VERSION "created by canmatrix"

NS_ :

BS_:

BU_: Host RT SYS MTR PWT DCDC EPS_C SEB HMI Any

BO_ 1 SAFETY_ESTOP_high: 0 Any

BO_ 1 SAFETY_ESTOP_low: 0 Any

BO_ 273 HMI_MODE_REQ_high: 2 Host
 SG_ req_mode : 7|8@0+ (1,0) [0|1] "" RT
 SG_ rolling_counter : 15|8@0+ (1,0) [0|255] "" RT

BO_ 274 HMI_PWR_REQ_high: 2 Host
 SG_ req_start : 7|8@0+ (1,0) [0|1] "" RT
 SG_ rolling_counter : 15|8@0+ (1,0) [0|255] "" RT

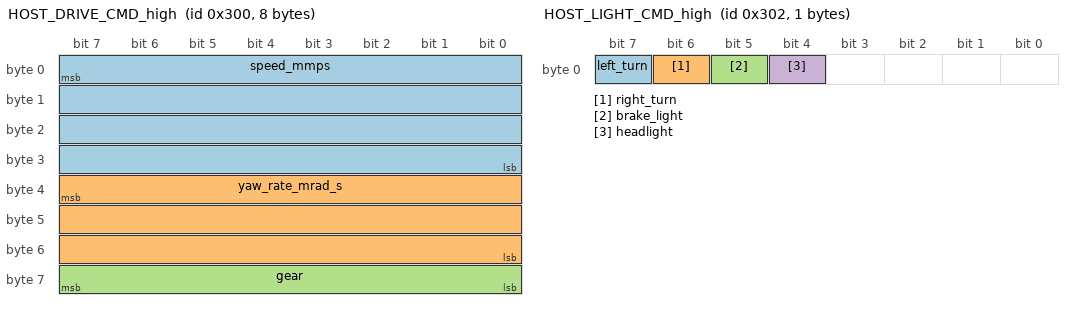
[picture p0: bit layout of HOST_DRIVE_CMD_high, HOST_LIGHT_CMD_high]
BO_ 768 HOST_DRIVE_CMD_high: 8 Host
 SG_ speed_mmps : 7|32@0- (1,0) [-500|3000] "" RT
 SG_ yaw_rate_mrad_s : 39|24@0- (1,0) [-3000|3000] "" RT
 SG_ gear : 63|8@0+ (1,0) [0|3] "" RT

BO_ 769 HOST_BRAKE_REQ_high: 4 Host
 SG_ brake_pressure_kpa : 7|32@0- (1,0) [0|20000] "" RT

BO_ 770 HOST_LIGHT_CMD_high: 1 Host
 SG_ left_turn : 7|1@0+ (1,0) [0|1] "" RT,SYS
 SG_ right_turn : 6|1@0+ (1,0) [0|1] "" RT,SYS
 SG_ brake_light : 5|1@0+ (1,0) [0|1] "" RT,SYS
 SG_ headlight : 4|1@0+ (1,0) [0|1] "" RT,SYS

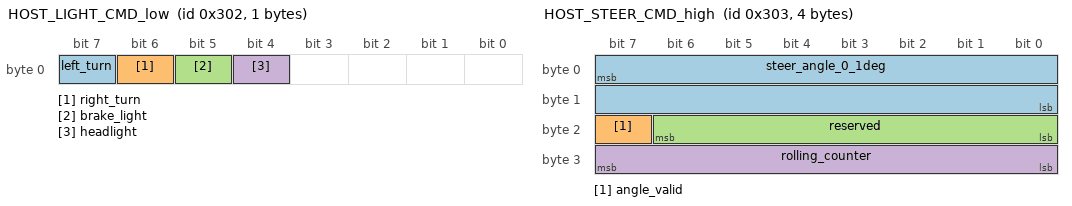
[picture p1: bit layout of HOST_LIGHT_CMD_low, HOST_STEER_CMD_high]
BO_ 770 HOST_LIGHT_CMD_low: 1 Host
 SG_ left_turn : 7|1@0+ (1,0) [0|1] "" RT,SYS
 SG_ right_turn : 6|1@0+ (1,0) [0|1] "" RT,SYS
 SG_ brake_light : 5|1@0+ (1,0) [0|1] "" RT,SYS
 SG_ headlight : 4|1@0+ (1,0) [0|1] "" RT,SYS

BO_ 771 HOST_STEER_CMD_high: 4 Host
 SG_ steer_angle_0_1deg : 7|16@0- (1,0) [-450|450] "" RT
 SG_ angle_valid : 23|1@0+ (1,0) [0|1] "" RT
 SG_ reserved : 22|7@0+ (1,0) [0|127] "" RT
 SG_ rolling_counter : 31|8@0+ (1,0) [0|255] "" RT

BO_ 1024 HOST_OBSTACLE_DIST_high: 4 Host
 SG_ distance_mm : 7|32@0+ (1,0) [0|4294967295] "" RT

BO_ 2044 HOST_HEARTBEAT_high: 2 Host
 SG_ alive_ctr : 7|8@0+ (1,0) [0|255] "" RT
 SG_ health_flags : 15|8@0+ (1,0) [0|255] "" RT

BO_ 288 SYS_THROTTLE_STS_low: 2 MTR
 SG_ speed_mmps : 7|16@0- (1,0) [-500|3000] "" RT,Host

BO_ 288 SYS_THROTTLE_STS_high: 2 MTR
 SG_ speed_mmps : 7|16@0- (1,0) [-500|3000] "" RT,Host

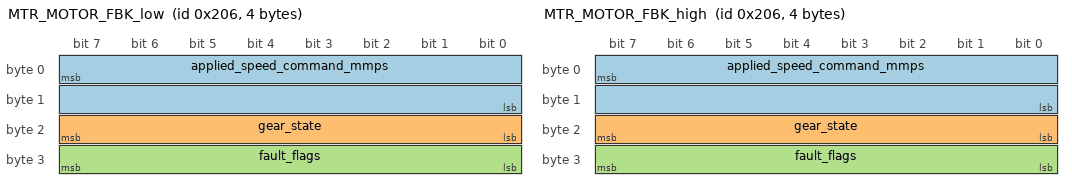
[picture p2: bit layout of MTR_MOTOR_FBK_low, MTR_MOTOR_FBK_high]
BO_ 518 MTR_MOTOR_FBK_low: 4 MTR
 SG_ applied_speed_command_mmps : 7|16@0- (1,0) [-500|3000] "" RT,SYS,Host
 SG_ gear_state : 23|8@0+ (1,0) [0|3] "" RT,SYS,Host
 SG_ fault_flags : 31|8@0+ (1,0) [0|255] "" RT,SYS,Host

BO_ 518 MTR_MOTOR_FBK_high: 4 MTR
 SG_ applied_speed_command_mmps : 7|16@0- (1,0) [-500|3000] "" RT,SYS,Host
 SG_ gear_state : 23|8@0+ (1,0) [0|3] "" RT,SYS,Host
 SG_ fault_flags : 31|8@0+ (1,0) [0|255] "" RT,SYS,Host

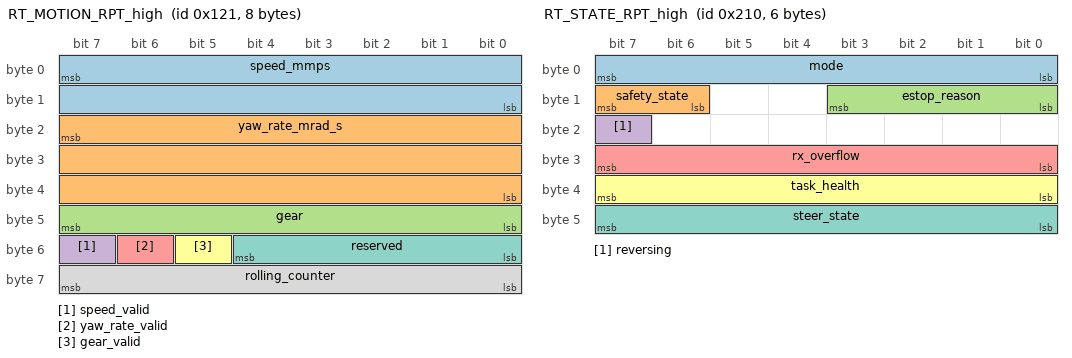
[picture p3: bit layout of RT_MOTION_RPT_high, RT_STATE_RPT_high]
BO_ 289 RT_MOTION_RPT_high: 8 RT
 SG_ speed_mmps : 7|16@0- (1,0) [-500|3000] "" Host
 SG_ yaw_rate_mrad_s : 23|24@0- (1,0) [-3000|3000] "" Host
 SG_ gear : 47|8@0+ (1,0) [0|3] "" Host
 SG_ speed_valid : 55|1@0+ (1,0) [0|1] "" Host
 SG_ yaw_rate_valid : 54|1@0+ (1,0) [0|1] "" Host
 SG_ gear_valid : 53|1@0+ (1,0) [0|1] "" Host
 SG_ reserved : 52|5@0+ (1,0) [0|31] "" Host
 SG_ rolling_counter : 63|8@0+ (1,0) [0|255] "" Host

BO_ 516 RT_DRIVE_CMD_low: 5 RT
 SG_ motor_speed_mmps : 7|32@0- (1,0) [-500|3000] "" SYS,MTR
 SG_ gear : 39|8@0+ (1,0) [0|3] "" SYS,MTR

BO_ 517 RT_BRAKE_CMD_low: 4 RT
 SG_ brake_pressure_kpa : 7|32@0- (1,0) [0|20000] "" SYS

BO_ 528 RT_STATE_RPT_high: 6 RT
 SG_ mode : 7|8@0+ (1,0) [0|2] "" Host,SYS
 SG_ safety_state : 15|2@0+ (1,0) [0|2] "" Host,SYS
 SG_ estop_reason : 11|4@0+ (1,0) [0|7] "" Host,SYS
 SG_ reversing : 23|1@0+ (1,0) [0|1] "" Host,SYS
 SG_ rx_overflow : 31|8@0+ (1,0) [0|255] "" Host,SYS
 SG_ task_health : 39|8@0+ (1,0) [0|255] "" Host,SYS
 SG_ steer_state : 47|8@0+ (1,0) [0|5] "" Host,SYS

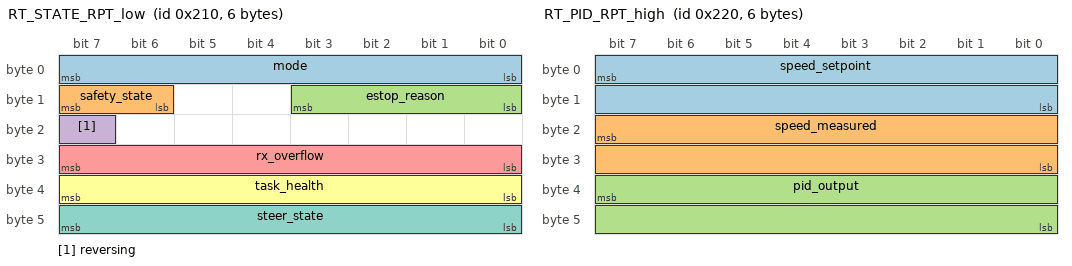
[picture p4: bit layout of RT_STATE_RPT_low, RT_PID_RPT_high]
BO_ 528 RT_STATE_RPT_low: 6 RT
 SG_ mode : 7|8@0+ (1,0) [0|2] "" Host,SYS
 SG_ safety_state : 15|2@0+ (1,0) [0|2] "" Host,SYS
 SG_ estop_reason : 11|4@0+ (1,0) [0|7] "" Host,SYS
 SG_ reversing : 23|1@0+ (1,0) [0|1] "" Host,SYS
 SG_ rx_overflow : 31|8@0+ (1,0) [0|255] "" Host,SYS
 SG_ task_health : 39|8@0+ (1,0) [0|255] "" Host,SYS
 SG_ steer_state : 47|8@0+ (1,0) [0|5] "" Host,SYS

BO_ 544 RT_PID_RPT_high: 6 RT
 SG_ speed_setpoint : 7|16@0- (1,0) [-32768|32767] "" Host
 SG_ speed_measured : 23|16@0- (1,0) [-32768|32767] "" Host
 SG_ pid_output : 39|16@0- (1,0) [-32768|32767] "" Host

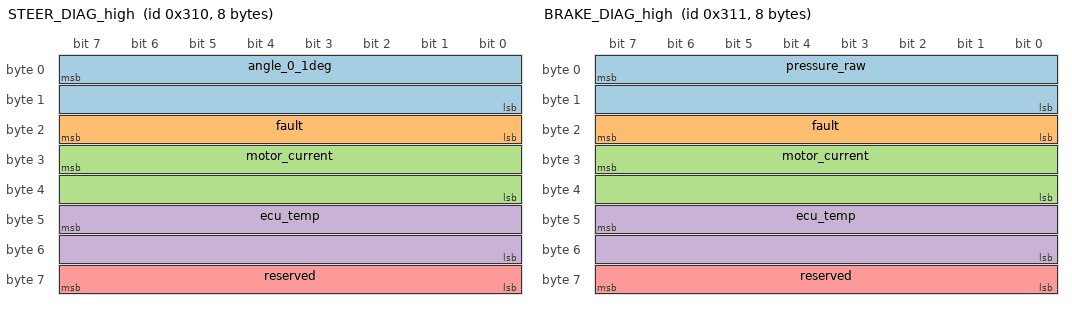
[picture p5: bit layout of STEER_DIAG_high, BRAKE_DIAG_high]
BO_ 784 STEER_DIAG_high: 8 RT
 SG_ angle_0_1deg : 7|16@0+ (0.1,-3000) [-3000|3553.5] "" Host
 SG_ fault : 23|8@0+ (1,0) [0|1] "" Host
 SG_ motor_current : 31|16@0+ (0.01,0) [0|655.35] "" Host
 SG_ ecu_temp : 47|16@0+ (0.1,0) [0|6553.5] "" Host
 SG_ reserved : 63|8@0+ (1,0) [0|255] "" Host

BO_ 785 BRAKE_DIAG_high: 8 RT
 SG_ pressure_raw : 7|16@0+ (0.05,0) [0|3276.75] "" Host
 SG_ fault : 23|8@0+ (1,0) [0|1] "" Host
 SG_ motor_current : 31|16@0+ (0.01,0) [0|655.35] "" Host
 SG_ ecu_temp : 47|16@0+ (0.1,0) [0|6553.5] "" Host
 SG_ reserved : 63|8@0+ (1,0) [0|255] "" Host

BO_ 2045 RT_HEARTBEAT_high: 2 RT
 SG_ alive_ctr : 7|8@0+ (1,0) [0|255] "" Host,SYS
 SG_ health_flags : 15|8@0+ (1,0) [0|255] "" Host,SYS

BO_ 2045 RT_HEARTBEAT_low: 2 RT
 SG_ alive_ctr : 7|8@0+ (1,0) [0|255] "" Host,SYS
 SG_ health_flags : 15|8@0+ (1,0) [0|255] "" Host,SYS

BO_ 1825 SEB_STATUS_low: 8 SEB

BO_ 1787 SEB_TEST_low: 8 SEB

BO_ 361 VCU_SES_REQ_low: 8 RT

BO_ 513 SES_STATUS_low: 8 EPS_C

BO_ 514 SES_ERR_INFO_low: 8 EPS_C

BO_ 515 SES_VERSION_low: 8 EPS_C

BO_ 1786 SES_TEST_low: 8 EPS_C

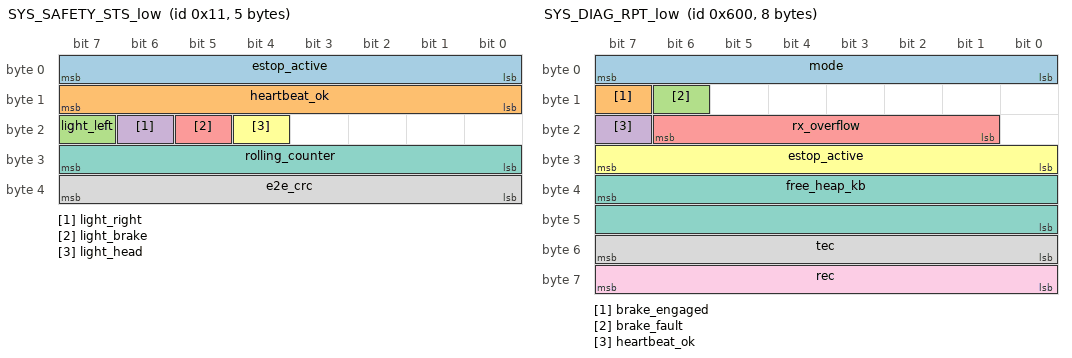
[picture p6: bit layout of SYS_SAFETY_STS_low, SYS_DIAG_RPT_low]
BO_ 17 SYS_SAFETY_STS_low: 5 SYS
 SG_ estop_active : 7|8@0+ (1,0) [0|1] "" RT,MTR
 SG_ heartbeat_ok : 15|8@0+ (1,0) [0|1] "" RT,MTR
 SG_ light_left : 23|1@0+ (1,0) [0|1] "" RT,MTR
 SG_ light_right : 22|1@0+ (1,0) [0|1] "" RT,MTR
 SG_ light_brake : 21|1@0+ (1,0) [0|1] "" RT,MTR
 SG_ light_head : 20|1@0+ (1,0) [0|1] "" RT,MTR
 SG_ rolling_counter : 31|8@0+ (1,0) [0|255] "" RT,MTR
 SG_ e2e_crc : 39|8@0+ (1,0) [0|255] "" RT,MTR

BO_ 272 SYS_MODE_CMD_low: 2 SYS
 SG_ mode : 7|8@0+ (1,0) [0|1] "" RT,MTR
 SG_ rolling_counter : 15|8@0+ (1,0) [0|255] "" RT,MTR

BO_ 1536 SYS_DIAG_RPT_low: 8 SYS
 SG_ mode : 7|8@0+ (1,0) [0|2] "" RT,Host
 SG_ brake_engaged : 15|1@0+ (1,0) [0|1] "" RT,Host
 SG_ brake_fault : 14|1@0+ (1,0) [0|1] "" RT,Host
 SG_ heartbeat_ok : 23|1@0+ (1,0) [0|1] "" RT,Host
 SG_ rx_overflow : 22|6@0+ (1,0) [0|63] "" RT,Host
 SG_ estop_active : 31|8@0+ (1,0) [0|1] "" RT,Host
 SG_ free_heap_kb : 39|16@0+ (1,0) [0|65535] "" RT,Host
 SG_ tec : 55|8@0+ (1,0) [0|255] "" RT,Host
 SG_ rec : 63|8@0+ (1,0) [0|255] "" RT,Host

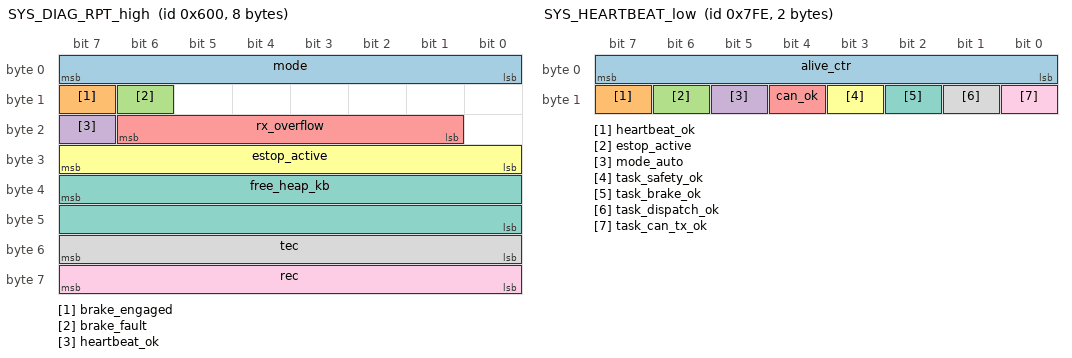
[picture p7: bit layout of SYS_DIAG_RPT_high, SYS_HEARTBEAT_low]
BO_ 1536 SYS_DIAG_RPT_high: 8 SYS
 SG_ mode : 7|8@0+ (1,0) [0|2] "" RT,Host
 SG_ brake_engaged : 15|1@0+ (1,0) [0|1] "" RT,Host
 SG_ brake_fault : 14|1@0+ (1,0) [0|1] "" RT,Host
 SG_ heartbeat_ok : 23|1@0+ (1,0) [0|1] "" RT,Host
 SG_ rx_overflow : 22|6@0+ (1,0) [0|63] "" RT,Host
 SG_ estop_active : 31|8@0+ (1,0) [0|1] "" RT,Host
 SG_ free_heap_kb : 39|16@0+ (1,0) [0|65535] "" RT,Host
 SG_ tec : 55|8@0+ (1,0) [0|255] "" RT,Host
 SG_ rec : 63|8@0+ (1,0) [0|255] "" RT,Host

BO_ 2046 SYS_HEARTBEAT_low: 2 SYS
 SG_ alive_ctr : 7|8@0+ (1,0) [0|255] "" RT
 SG_ heartbeat_ok : 15|1@0+ (1,0) [0|1] "" RT
 SG_ estop_active : 14|1@0+ (1,0) [0|1] "" RT
 SG_ mode_auto : 13|1@0+ (1,0) [0|1] "" RT
 SG_ can_ok : 12|1@0+ (1,0) [0|1] "" RT
 SG_ task_safety_ok : 11|1@0+ (1,0) [0|1] "" RT
 SG_ task_brake_ok : 10|1@0+ (1,0) [0|1] "" RT
 SG_ task_dispatch_ok : 9|1@0+ (1,0) [0|1] "" RT
 SG_ task_can_tx_ok : 8|1@0+ (1,0) [0|1] "" RT

CM_ BO_ 273  "Mode requests are produced by Host (acting as the logical HMI role) and forwarded by RT to SYS, which remains the sole mode authority.";

BA_DEF_ BO_ "GenMsgCycleTime" INT 0 65535;

BA_ "GenMsgCycleTime" BO_ 273 1000;
BA_ "GenMsgCycleTime" BO_ 274 1000;
BA_ "GenMsgCycleTime" BO_ 768 10;
BA_ "GenMsgCycleTime" BO_ 771 10;
BA_ "GenMsgCycleTime" BO_ 1024 100;
BA_ "GenMsgCycleTime" BO_ 2044 500;
BA_ "GenMsgCycleTime" BO_ 288 10;
BA_ "GenMsgCycleTime" BO_ 288 10;
BA_ "GenMsgCycleTime" BO_ 518 20;
BA_ "GenMsgCycleTime" BO_ 518 20;
BA_ "GenMsgCycleTime" BO_ 289 10;
BA_ "GenMsgCycleTime" BO_ 516 10;
BA_ "GenMsgCycleTime" BO_ 517 20;
BA_ "GenMsgCycleTime" BO_ 528 100;
BA_ "GenMsgCycleTime" BO_ 528 100;
BA_ "GenMsgCycleTime" BO_ 544 100;
BA_ "GenMsgCycleTime" BO_ 784 100;
BA_ "GenMsgCycleTime" BO_ 785 100;
BA_ "GenMsgCycleTime" BO_ 2045 500;
BA_ "GenMsgCycleTime" BO_ 2045 500;
BA_ "GenMsgCycleTime" BO_ 1825 10;
BA_ "GenMsgCycleTime" BO_ 1787 10;
BA_ "GenMsgCycleTime" BO_ 361 20;
BA_ "GenMsgCycleTime" BO_ 513 10;
BA_ "GenMsgCycleTime" BO_ 514 100;
BA_ "GenMsgCycleTime" BO_ 515 1000;
BA_ "GenMsgCycleTime" BO_ 1786 10;
BA_ "GenMsgCycleTime" BO_ 17 200;
BA_ "GenMsgCycleTime" BO_ 272 100;
BA_ "GenMsgCycleTime" BO_ 1536 1000;
BA_ "GenMsgCycleTime" BO_ 1536 1000;
BA_ "GenMsgCycleTime" BO_ 2046 100;

VAL_ 273 req_mode 0 "MANUAL" 1 "AUTO";
VAL_ 274 req_start 0 "OFF" 1 "ON";
VAL_ 768 gear 0 "N" 1 "D" 2 "S" 3 "R";
VAL_ 1024 distance_mm 4294967295 "clear";
VAL_ 289 gear 0 "N" 1 "D" 2 "S" 3 "R";
VAL_ 516 gear 0 "N" 1 "D" 2 "S" 3 "R";
VAL_ 528 mode 0 "MANUAL" 1 "AUTO" 2 "ESTOP";
VAL_ 528 mode 0 "MANUAL" 1 "AUTO" 2 "ESTOP";
VAL_ 272 mode 0 "MANUAL" 1 "AUTO";
VAL_ 1536 mode 0 "MANUAL" 1 "AUTO" 2 "ESTOP";
VAL_ 1536 mode 0 "MANUAL" 1 "AUTO" 2 "ESTOP";
